# STM32F100 register map
File version: 1.1
CPU: CM3 r1p1, little endian, no MPU, no FPU, 4 interrupt priority bits
Registers are 32-bit, read-write, reset 0x0 unless marked. A register's access mark holds for its fields unless they carry their own. Offsets are from the block's base; [hi:lo] are bit positions; lines under a group give offsets from that group; {n}, {i} and the like mark numbered series; 'fields as' and 'values as' point back to an identical list.

## DMA1 — DMA controller
Base 0x40020000
Same registers: DMA2 0x40020400
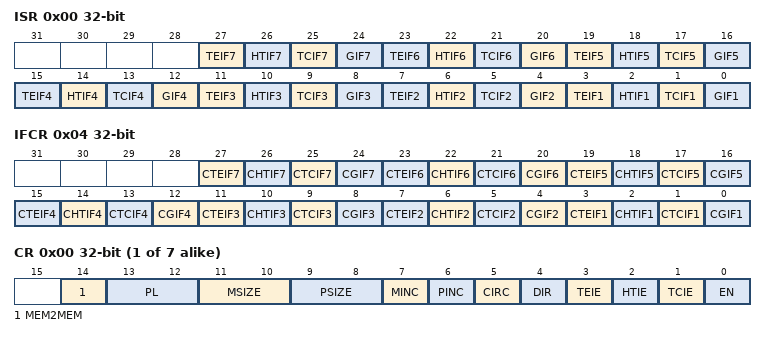
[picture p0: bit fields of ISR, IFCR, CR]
0x00 ISR ro — DMA interrupt status register (DMA_ISR)
  [4n-1] TEIF{n} (n=1..7) — Channel {n} Transfer Error flag
    0=NoError (No transfer error); 1=Error (A transfer error has occured)
  [4n-2] HTIF{n} (n=1..7) — Channel {n} Half Transfer Complete flag
    0=NotHalf (No half transfer event); 1=Half (A half transfer event has occured)
  [4n-3] TCIF{n} (n=1..7) — Channel {n} Transfer Complete flag
    0=NotComplete (No transfer complete event); 1=Complete (A transfer complete event has occured)
  [4n-4] GIF{n} (n=1..7) — Channel {n} Global interrupt flag
    0=NoEvent (No transfer error, half event, complete event); 1=Event (A transfer error, half event or complete event has occured)
0x04 IFCR wo — DMA interrupt flag clear register (DMA_IFCR)
  [4n-1] CTEIF{n} (n=1..7) — Channel {n} Transfer Error clear
    1=Clears the TEIF flag in the ISR register
  [4n-2] CHTIF{n} (n=1..7) — Channel {n} Half Transfer clear
    1=Clears the HTIF flag in the ISR register
  [4n-3] CTCIF{n} (n=1..7) — Channel {n} Transfer Complete clear
    1=Clears the TCIF flag in the ISR register
  [4n-4] CGIF{n} (n=1..7) — Channel {n} Global interrupt clear
    1=Clears the GIF, TEIF, HTIF, TCIF flags in the ISR register
0x08 CH{i} (i=1..7; step 0x14) group — Channel cluster: CCR?, CNDTR?, CPAR?, and CMAR? registers
  0x00 CR — DMA channel configuration register (DMA_CCR)
    [14] MEM2MEM — Memory to memory mode
      0=Disabled (Memory to memory mode disabled); 1=Enabled (Memory to memory mode enabled)
    [13:12] PL — Channel Priority level
      0=Low (Low priority); 1=Medium priority; 2=High priority; 3=Very high priority
    [11:10] MSIZE — Memory size
      0=Bits8 (8-bit size); 1=Bits16 (16-bit size); 2=Bits32 (32-bit size)
    [9:8] PSIZE — Peripheral size
      values as MSIZE
    [7] MINC — Memory increment mode
      0=Disabled (Increment mode disabled); 1=Enabled (Increment mode enabled)
    [6] PINC — Peripheral increment mode
      values as MINC
    [5] CIRC — Circular mode
      0=Disabled (Circular buffer disabled); 1=Enabled (Circular buffer enabled)
    [4] DIR — Data transfer direction
      0=FromPeripheral (Read from peripheral); 1=FromMemory (Read from memory)
    [3] TEIE — Transfer error interrupt enable
      0=Disabled (Transfer Error interrupt disabled); 1=Enabled (Transfer Error interrupt enabled)
    [2] HTIE — Half Transfer interrupt enable
      0=Disabled (Half Transfer interrupt disabled); 1=Enabled (Half Transfer interrupt enabled)
    [1] TCIE — Transfer complete interrupt enable
      0=Disabled (Transfer Complete interrupt disabled); 1=Enabled (Transfer Complete interrupt enabled)
    [0] EN — Channel enable
      0=Disabled (Channel disabled); 1=Enabled (Channel enabled)
  0x04 NDTR — DMA channel 1 number of data register
    [15:0] NDT — Number of data to transfer
  0x08 PAR — DMA channel 1 peripheral address register
    [31:0] PA — Peripheral address
  0x0C MAR — DMA channel 1 memory address register
    [31:0] MA — Memory address

## RTC — Real time clock
Base 0x40002800
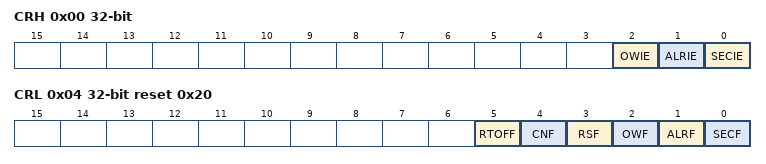
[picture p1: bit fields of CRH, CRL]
0x00 CRH — RTC Control Register High
  [2] OWIE — Overflow interrupt Enable
    0=Disabled (Overflow interrupt is masked); 1=Enabled (Overflow interrupt is enabled)
  [1] ALRIE — Alarm interrupt Enable
    0=Disabled (Alarm interrupt is masked); 1=Enabled (Alarm interrupt is enabled)
  [0] SECIE — Second interrupt Enable
    0=Disabled (Second interrupt is masked); 1=Enabled (Second interrupt is enabled)
0x04 CRL access per field reset 0x20 — RTC Control Register Low
  [5] RTOFF ro — RTC operation OFF
    0=Enabled (Last write operation on RTC registers is still ongoing); 1=Disabled (Last write operation on RTC registers terminated)
  [4] CNF rw — Configuration Flag
    0=Exit configuration mode (start update of RTC registers); 1=Enter configuration mode
  [3] RSF rw write-0-clears — Registers Synchronized Flag
    on read: 0=NotSynchronized (Registers not yet synchronized); 1=Synchronized (Registers synchronized) | on write: 0=Clear flag
  [2] OWF rw write-0-clears — Overflow Flag
    on read: 0=NoOverflow (Overflow not detected); 1=Overflow (32-bit programmable counter overflow occurred) | on write: 0=Clear flag
  [1] ALRF rw write-0-clears — Alarm Flag
    on read: 0=NoAlarm (Alarm not detected); 1=Alarm detected | on write: 0=Clear flag
  [0] SECF rw write-0-clears — Second Flag
    on read: 0=NoPrescalerOverflow (Second flag condition not met); 1=PrescalerOverflow (Second flag condition met) | on write: 0=Clear flag
0x08 PRLH wo — RTC Prescaler Load Register High
  [3:0] PRLH
0x0C PRLL wo reset 0x8000 — RTC Prescaler Load Register Low
  [15:0] PRLL — RTC Prescaler Divider Register Low
0x10 DIVH ro — RTC Prescaler Divider Register High
  [3:0] DIVH — RTC prescaler divider register high
0x14 DIVL ro reset 0x8000 — RTC Prescaler Divider Register Low
  [15:0] DIVL — RTC prescaler divider register Low
0x18 CNTH — RTC Counter Register High
  [15:0] CNTH — RTC counter register high
0x1C CNTL — RTC Counter Register Low
  [15:0] CNTL — RTC counter register Low
0x20 ALRH wo reset 0xFFFF — RTC Alarm Register High
  [15:0] ALRH — RTC alarm register high
0x24 ALRL wo reset 0xFFFF — RTC Alarm Register Low
  [15:0] ALRL — RTC alarm register low
